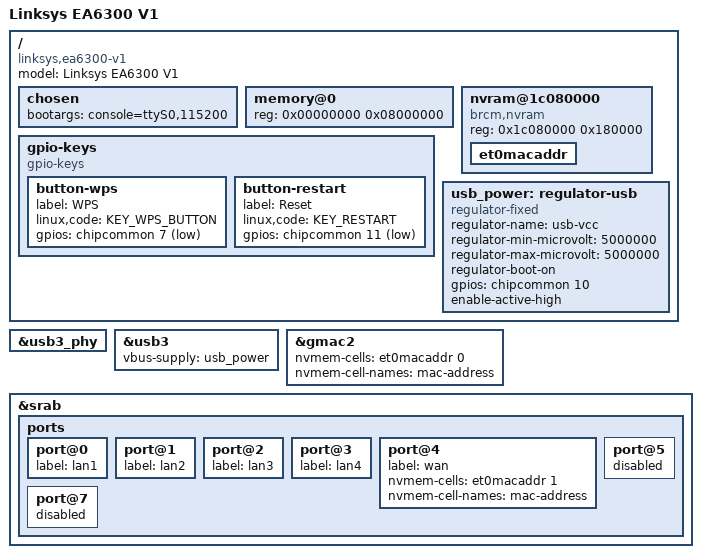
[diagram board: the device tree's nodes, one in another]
// SPDX-License-Identifier: GPL-2.0-or-later OR MIT
/*
 * Copyright (C) 2017 Rafał Miłecki <rafal@milecki.pl>
 */

/dts-v1/;

#include "bcm4708.dtsi"
#include "bcm5301x-nand-cs0-bch8.dtsi"

/ {
	compatible = "linksys,ea6300-v1", "brcm,bcm4708";
	model = "Linksys EA6300 V1";

	chosen {
		bootargs = "console=ttyS0,115200";
	};

	memory@0 {
		device_type = "memory";
		reg = <0x00000000 0x08000000>;
	};

	nvram@1c080000 {
		compatible = "brcm,nvram";
		reg = <0x1c080000 0x180000>;

		et0macaddr: et0macaddr {
			#nvmem-cell-cells = <1>;
		};
	};

	gpio-keys {
		compatible = "gpio-keys";

		button-wps {
			label = "WPS";
			linux,code = <KEY_WPS_BUTTON>;
			gpios = <&chipcommon 7 GPIO_ACTIVE_LOW>;
		};

		button-restart {
			label = "Reset";
			linux,code = <KEY_RESTART>;
			gpios = <&chipcommon 11 GPIO_ACTIVE_LOW>;
		};
	};
};

&usb3_phy {
	status = "okay";
};

/ {
	usb_power: regulator-usb {
		compatible = "regulator-fixed";
		regulator-name = "usb-vcc";
		regulator-min-microvolt = <5000000>;
		regulator-max-microvolt = <5000000>;
		regulator-boot-on;
		gpios = <&chipcommon 10 GPIO_ACTIVE_HIGH>;
		enable-active-high;
	};
};

&usb3 {
	vbus-supply = <&usb_power>;
};

&gmac2 {
	nvmem-cells = <&et0macaddr 0>;
	nvmem-cell-names = "mac-address";
};

&srab {
	status = "okay";

	ports {
		port@0 {
			label = "lan1";
		};

		port@1 {
			label = "lan2";
		};

		port@2 {
			label = "lan3";
		};

		port@3 {
			label = "lan4";
		};

		port@4 {
			label = "wan";

			nvmem-cells = <&et0macaddr 1>;
			nvmem-cell-names = "mac-address";
		};

		port@5 {
			status = "disabled";
		};

		port@7 {
			status = "disabled";
		};
	};
};
